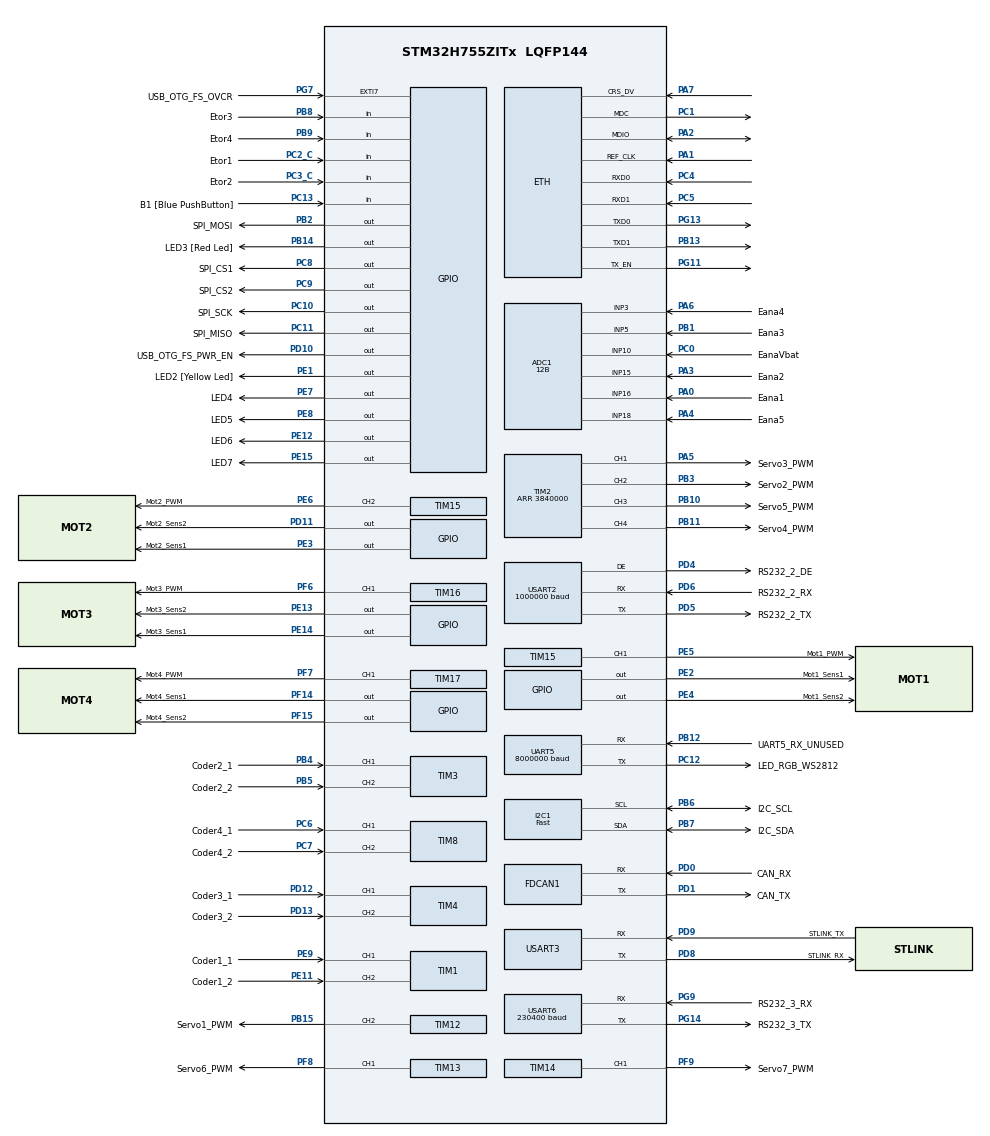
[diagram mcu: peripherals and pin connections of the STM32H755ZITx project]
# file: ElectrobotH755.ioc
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ADC1.Channel-0\#ChannelRegularConversion=ADC_CHANNEL_3
ADC1.ContinuousConvMode=DISABLE
ADC1.NbrOfConversion=1
ADC1.NbrOfConversionFlag=1
ADC1.OffsetNumber-0\#ChannelRegularConversion=ADC_OFFSET_NONE
ADC1.OffsetSignedSaturation-0\#ChannelRegularConversion=DISABLE
ADC1.Rank-0\#ChannelRegularConversion=1
ADC1.Resolution=ADC_RESOLUTION_12B
ADC1.SamplingTime-0\#ChannelRegularConversion=ADC_SAMPLETIME_1CYCLE_5
ADC1.master=1
CortexM4.IPs=FATFS_M4\:I,FREERTOS_M4\:I,IWDG2\:I,RCC,WWDG2\:I,DMA,BDMA,MDMA,NVIC2\:I,DEBUG,USB_DEVICE_M4\:I,USB_HOST_M4\:I,PDM2PCM_M4\:I,PWR,RESMGR_UTILITY,SYS_M4\:I,CORTEX_M4\:I,OPENAMP_M4\:I,VREFBUF,GPIO
CortexM7.IPs=FATFS_M7\:I,FREERTOS_M7\:I,IWDG1\:I,RCC\:I,WWDG1\:I,DMA\:I,BDMA\:I,MDMA\:I,NVIC1\:I,USART3\:I,SYS\:I,CORTEX_M7\:I,DEBUG\:I,USB_DEVICE_M7\:I,USB_HOST_M7\:I,PDM2PCM_M7\:I,PWR\:I,RESMGR_UTILITY\:I,OPENAMP_M7\:I,VREFBUF\:I,GPIO\:I,I2C1\:I,TIM15\:I,TIM1\:I,TIM4\:I,TIM16\:I,TIM17\:I,TIM8\:I,USART2\:I,USART6\:I,ADC1\:I,TIM3\:I,TIM2\:I,SPI3\:I,FDCAN1\:I,TIM12\:I,TIM13\:I,TIM14\:I,MEMORYMAP\:I,UART5\:I,ETH\:I,RNG\:I
CortexM7.Pins=PE2,PE3,PE4,PC2_C,PC3_C,PB2,PF14,PF15,PE7,PE8,PE12,PE13,PE14,PE15,PB14,PD10,PD11,PC8,PC9,PC10,PC11,PB8,PB9,PE1
Dma.Request0=USART3_TX
Dma.Request1=UART5_TX
Dma.Request2=USART6_RX
Dma.UART5_TX.1.Direction=DMA_MEMORY_TO_PERIPH
Dma.UART5_TX.1.EventEnable=DISABLE
Dma.UART5_TX.1.FIFOMode=DMA_FIFOMODE_DISABLE
Dma.UART5_TX.1.Instance=DMA1_Stream1
Dma.UART5_TX.1.MemDataAlignment=DMA_MDATAALIGN_BYTE
Dma.UART5_TX.1.MemInc=DMA_MINC_ENABLE
Dma.UART5_TX.1.Mode=DMA_NORMAL
Dma.UART5_TX.1.PeriphDataAlignment=DMA_PDATAALIGN_BYTE
Dma.UART5_TX.1.PeriphInc=DMA_PINC_DISABLE
Dma.UART5_TX.1.Polarity=HAL_DMAMUX_REQ_GEN_RISING
Dma.UART5_TX.1.Priority=DMA_PRIORITY_LOW
Dma.UART5_TX.1.RequestNumber=1
Dma.UART5_TX.1.SignalID=NONE
Dma.UART5_TX.1.SyncEnable=DISABLE
Dma.UART5_TX.1.SyncPolarity=HAL_DMAMUX_SYNC_NO_EVENT
Dma.UART5_TX.1.SyncRequestNumber=1
Dma.UART5_TX.1.SyncSignalID=NONE
Dma.USART3_TX.0.Direction=DMA_MEMORY_TO_PERIPH
Dma.USART3_TX.0.EventEnable=DISABLE
Dma.USART3_TX.0.FIFOMode=DMA_FIFOMODE_DISABLE
Dma.USART3_TX.0.Instance=DMA1_Stream0
Dma.USART3_TX.0.MemDataAlignment=DMA_MDATAALIGN_BYTE
Dma.USART3_TX.0.MemInc=DMA_MINC_ENABLE
Dma.USART3_TX.0.Mode=DMA_NORMAL
Dma.USART3_TX.0.PeriphDataAlignment=DMA_PDATAALIGN_BYTE
Dma.USART3_TX.0.PeriphInc=DMA_PINC_DISABLE
Dma.USART3_TX.0.Polarity=HAL_DMAMUX_REQ_GEN_RISING
Dma.USART3_TX.0.Priority=DMA_PRIORITY_LOW
Dma.USART3_TX.0.RequestNumber=1
Dma.USART3_TX.0.SignalID=NONE
Dma.USART3_TX.0.SyncEnable=DISABLE
Dma.USART3_TX.0.SyncPolarity=HAL_DMAMUX_SYNC_NO_EVENT
Dma.USART3_TX.0.SyncRequestNumber=1
Dma.USART3_TX.0.SyncSignalID=NONE
Dma.USART6_RX.2.Direction=DMA_PERIPH_TO_MEMORY
Dma.USART6_RX.2.EventEnable=DISABLE
Dma.USART6_RX.2.FIFOMode=DMA_FIFOMODE_DISABLE
Dma.USART6_RX.2.Instance=DMA1_Stream2
Dma.USART6_RX.2.MemDataAlignment=DMA_MDATAALIGN_BYTE
Dma.USART6_RX.2.MemInc=DMA_MINC_ENABLE
Dma.USART6_RX.2.Mode=DMA_NORMAL
Dma.USART6_RX.2.PeriphDataAlignment=DMA_PDATAALIGN_BYTE
Dma.USART6_RX.2.PeriphInc=DMA_PINC_DISABLE
Dma.USART6_RX.2.Polarity=HAL_DMAMUX_REQ_GEN_RISING
Dma.USART6_RX.2.Priority=DMA_PRIORITY_LOW
Dma.USART6_RX.2.RequestNumber=1
Dma.USART6_RX.2.SignalID=NONE
Dma.USART6_RX.2.SyncEnable=DISABLE
Dma.USART6_RX.2.SyncPolarity=HAL_DMAMUX_SYNC_NO_EVENT
Dma.USART6_RX.2.SyncRequestNumber=1
Dma.USART6_RX.2.SyncSignalID=NONE
ETH.MediaInterface=HAL_ETH_RMII_MODE
FDCAN1.CalculateBaudRateNominal=1791666
FDCAN1.CalculateTimeBitNominal=558
FDCAN1.CalculateTimeQuantumNominal=186.04651162790697
I2C1.I2C_Speed_Mode=I2C_Fast
I2C1.Timing=0x009032AE
Mcu.Family=STM32H7
Mcu.Name=STM32H755ZITx
Mcu.Package=LQFP144
NVIC1.DMA1_Stream0_IRQn=true\:0\:0\:false\:false\:true\:false\:true\:true
NVIC1.DMA1_Stream1_IRQn=true\:0\:0\:false\:false\:true\:false\:true\:true
NVIC1.DMA1_Stream2_IRQn=true\:5\:0\:true\:false\:true\:false\:true\:true
NVIC1.ETH_IRQn=true\:0\:0\:false\:false\:false\:true\:true\:true
NVIC1.PriorityGroup=NVIC_PRIORITYGROUP_4
NVIC1.UART5_IRQn=true\:0\:0\:false\:false\:true\:true\:true\:true
NVIC1.USART3_IRQn=true\:6\:0\:true\:false\:true\:true\:true\:true
NVIC1.USART6_IRQn=true\:5\:0\:true\:false\:true\:true\:true\:true
NVIC2.PriorityGroup=NVIC_PRIORITYGROUP_4
PA0.GPIO_Label=Eana1
PA0.Mode=IN16-Single-Ended
PA0.PinAttribute=CortexM7
PA0.Signal=ADC1_INP16
PA1.Mode=RMII
PA1.PinAttribute=CortexM7
PA1.Signal=ETH_REF_CLK
PA11.PinAttribute=CortexM7
PA11.Signal=USB_OTG_FS_DM
PA12.PinAttribute=CortexM7
PA12.Signal=USB_OTG_FS_DP
PA2.Mode=RMII
PA2.PinAttribute=CortexM7
PA2.Signal=ETH_MDIO
PA3.GPIO_Label=Eana2
PA3.PinAttribute=CortexM7
PA3.Signal=ADCx_INP15
PA4.GPIO_Label=Eana5
PA4.PinAttribute=CortexM7
PA4.Signal=ADCx_INP18
PA5.GPIO_Label=Servo3_PWM
PA5.PinAttribute=CortexM7
PA5.Signal=S_TIM2_CH1_ETR
PA6.GPIO_Label=Eana4
PA6.PinAttribute=CortexM7
PA6.Signal=ADCx_INP3
PA7.Mode=RMII
PA7.PinAttribute=CortexM7
PA7.Signal=ETH_CRS_DV
PA8.PinAttribute=CortexM7
PA8.Signal=USB_OTG_FS_SOF
PA9.PinAttribute=CortexM7
PA9.Signal=USB_OTG_FS_VBUS
PB0.PinAttribute=CortexM7
PB0.Signal=ETH_RXD2
PB1.GPIO_Label=Eana3
PB1.PinAttribute=CortexM7
PB1.Signal=ADCx_INP5
PB10.GPIO_Label=Servo5_PWM
PB10.PinAttribute=CortexM7
PB10.Signal=S_TIM2_CH3
PB11.GPIO_Label=Servo4_PWM
PB11.PinAttribute=CortexM7
PB11.Signal=S_TIM2_CH4
PB12.GPIO_Label=UART5_RX_UNUSED
PB12.Mode=Asynchronous
PB12.PinAttribute=CortexM7
PB12.Signal=UART5_RX
PB13.Mode=RMII
PB13.PinAttribute=CortexM7
PB13.Signal=ETH_TXD1
PB14.GPIO_Label=LED3 [Red Led]
PB14.PinAttribute=CortexM7
PB14.PinState=GPIO_PIN_SET
PB14.Signal=GPIO_Output
PB15.GPIO_Label=Servo1_PWM
PB15.PinAttribute=CortexM7
PB15.Signal=S_TIM12_CH2
PB2.GPIO_Label=SPI_MOSI
PB2.PinAttribute=CortexM7
PB2.Signal=GPIO_Output
PB3\ (JTDO/TRACESWO).GPIO_Label=Servo2_PWM
PB3\ (JTDO/TRACESWO).PinAttribute=CortexM7
PB3\ (JTDO/TRACESWO).Signal=S_TIM2_CH2
PB4\ (NJTRST).GPIO_Label=Coder2_1
PB4\ (NJTRST).PinAttribute=CortexM7
PB4\ (NJTRST).Signal=S_TIM3_CH1
PB5.GPIO_Label=Coder2_2
PB5.PinAttribute=CortexM7
PB5.Signal=S_TIM3_CH2
PB6.GPIO_Label=I2C_SCL
PB6.GPIO_Pu=GPIO_NOPULL
PB6.GPIO_Speed=GPIO_SPEED_FREQ_VERY_HIGH
PB6.Mode=I2C
PB6.PinAttribute=CortexM7
PB6.Signal=I2C1_SCL
PB7.GPIO_Label=I2C_SDA
PB7.GPIO_Pu=GPIO_NOPULL
PB7.GPIO_Speed=GPIO_SPEED_FREQ_VERY_HIGH
PB7.Mode=I2C
PB7.PinAttribute=CortexM7
PB7.Signal=I2C1_SDA
PB8.GPIO_Label=Etor3
PB8.GPIO_PuPd=GPIO_PULLUP
PB8.PinAttribute=CortexM7
PB8.Signal=GPIO_Input
PB9.GPIO_Label=Etor4
PB9.GPIO_PuPd=GPIO_PULLUP
PB9.PinAttribute=CortexM7
PB9.Signal=GPIO_Input
PC0.GPIO_Label=EanaVbat
PC0.PinAttribute=CortexM7
PC0.Signal=ADCx_INP10
PC1.Mode=RMII
PC1.PinAttribute=CortexM7
PC1.Signal=ETH_MDC
PC10.GPIO_Label=SPI_SCK
PC10.PinAttribute=CortexM7
PC10.Signal=GPIO_Output
PC11.GPIO_Label=SPI_MISO
PC11.PinAttribute=CortexM7
PC11.Signal=GPIO_Output
PC12.GPIO_Label=LED_RGB_WS2812
PC12.Mode=Asynchronous
PC12.PinAttribute=CortexM7
PC12.Signal=UART5_TX
PC13.GPIO_Label=B1 [Blue PushButton]
PC13.PinAttribute=Free
PC13.Signal=GPIO_Input
PC14-OSC32_IN\ (OSC32_IN).Mode=LSE-External-Oscillator
PC14-OSC32_IN\ (OSC32_IN).PinAttribute=CortexM7
PC14-OSC32_IN\ (OSC32_IN).Signal=RCC_OSC32_IN
PC15-OSC32_OUT\ (OSC32_OUT).Mode=LSE-External-Oscillator
PC15-OSC32_OUT\ (OSC32_OUT).PinAttribute=CortexM7
PC15-OSC32_OUT\ (OSC32_OUT).Signal=RCC_OSC32_OUT
PC2_C.GPIO_Label=Etor1
PC2_C.GPIO_PuPd=GPIO_PULLUP
PC2_C.PinAttribute=CortexM7
PC2_C.Signal=GPIO_Input
PC3_C.GPIO_Label=Etor2
PC3_C.GPIO_PuPd=GPIO_PULLUP
PC3_C.PinAttribute=CortexM7
PC3_C.Signal=GPIO_Input
PC4.Mode=RMII
PC4.PinAttribute=CortexM7
PC4.Signal=ETH_RXD0
PC5.Mode=RMII
PC5.PinAttribute=CortexM7
PC5.Signal=ETH_RXD1
PC6.GPIO_Label=Coder4_1
PC6.PinAttribute=CortexM7
PC6.Signal=S_TIM8_CH1
PC7.GPIO_Label=Coder4_2
PC7.PinAttribute=CortexM7
PC7.Signal=S_TIM8_CH2
PC8.GPIO_Label=SPI_CS1
PC8.PinAttribute=CortexM7
PC8.Signal=GPIO_Output
PC9.GPIO_Label=SPI_CS2
PC9.PinAttribute=CortexM7
PC9.Signal=GPIO_Output
PD0.GPIO_Label=CAN_RX
PD0.Mode=FDCAN_Activate
PD0.PinAttribute=CortexM7
PD0.Signal=FDCAN1_RX
PD1.GPIO_Label=CAN_TX
PD1.GPIO_PuPd=GPIO_PULLUP
PD1.Mode=FDCAN_Activate
PD1.PinAttribute=CortexM7
PD1.Signal=FDCAN1_TX
PD10.GPIO_Label=USB_OTG_FS_PWR_EN
PD10.PinAttribute=CortexM7
PD10.Signal=GPIO_Output
PD11.GPIO_Label=Mot2_Sens2
PD11.PinAttribute=CortexM7
PD11.Signal=GPIO_Output
PD12.GPIO_Label=Coder3_1
PD12.PinAttribute=CortexM7
PD12.Signal=S_TIM4_CH1
PD13.GPIO_Label=Coder3_2
PD13.PinAttribute=CortexM7
PD13.Signal=S_TIM4_CH2
PD4.GPIO_Label=RS232_2_DE
PD4.Mode=Hardware Flow Control (RS485)
PD4.PinAttribute=CortexM7
PD4.Signal=USART2_DE
PD5.GPIO_Label=RS232_2_TX
PD5.Mode=Asynchronous
PD5.PinAttribute=CortexM7
PD5.Signal=USART2_TX
PD6.GPIO_Label=RS232_2_RX
PD6.Mode=Asynchronous
PD6.PinAttribute=CortexM7
PD6.Signal=USART2_RX
PD8.GPIO_Label=STLINK_RX
PD8.Mode=Asynchronous
PD8.PinAttribute=CortexM7
PD8.Signal=USART3_TX
PD9.GPIO_Label=STLINK_TX
PD9.Mode=Asynchronous
PD9.PinAttribute=CortexM7
PD9.Signal=USART3_RX
PE1.GPIO_Label=LED2 [Yellow Led]
PE1.PinAttribute=CortexM7
PE1.Signal=GPIO_Output
PE11.GPIO_Label=Coder1_2
PE11.PinAttribute=CortexM7
PE11.Signal=S_TIM1_CH2
PE12.GPIO_Label=LED6
PE12.PinAttribute=CortexM7
PE12.Signal=GPIO_Output
PE13.GPIO_Label=Mot3_Sens2
PE13.PinAttribute=CortexM7
PE13.Signal=GPIO_Output
PE14.GPIO_Label=Mot3_Sens1
PE14.PinAttribute=CortexM7
PE14.Signal=GPIO_Output
PE15.GPIO_Label=LED7
PE15.PinAttribute=CortexM7
PE15.Signal=GPIO_Output
PE2.GPIO_Label=Mot1_Sens1
PE2.PinAttribute=CortexM7
PE2.Signal=GPIO_Output
PE3.GPIO_Label=Mot2_Sens1
PE3.PinAttribute=CortexM7
PE3.Signal=GPIO_Output
PE4.GPIO_Label=Mot1_Sens2
PE4.PinAttribute=CortexM7
PE4.Signal=GPIO_Output
PE5.GPIO_Label=Mot1_PWM
PE5.PinAttribute=CortexM7
PE5.Signal=S_TIM15_CH1
PE6.GPIO_Label=Mot2_PWM
PE6.PinAttribute=CortexM7
PE6.Signal=S_TIM15_CH2
PE7.GPIO_Label=LED4
PE7.PinAttribute=CortexM7
PE7.Signal=GPIO_Output
PE8.GPIO_Label=LED5
PE8.PinAttribute=CortexM7
PE8.Signal=GPIO_Output
PE9.GPIO_Label=Coder1_1
PE9.PinAttribute=CortexM7
PE9.Signal=S_TIM1_CH1
PF14.GPIO_Label=Mot4_Sens1
PF14.PinAttribute=CortexM7
PF14.Signal=GPIO_Output
PF15.GPIO_Label=Mot4_Sens2
PF15.PinAttribute=CortexM7
PF15.Signal=GPIO_Output
PF6.GPIO_Label=Mot3_PWM
PF6.PinAttribute=CortexM7
PF6.Signal=S_TIM16_CH1
PF7.GPIO_Label=Mot4_PWM
PF7.PinAttribute=CortexM7
PF7.Signal=S_TIM17_CH1
PF8.GPIO_Label=Servo6_PWM
PF8.PinAttribute=CortexM7
PF8.Signal=S_TIM13_CH1
PF9.GPIO_Label=Servo7_PWM
PF9.PinAttribute=CortexM7
PF9.Signal=S_TIM14_CH1
PG11.Mode=RMII
PG11.PinAttribute=CortexM7
PG11.Signal=ETH_TX_EN
PG13.Mode=RMII
PG13.PinAttribute=CortexM7
PG13.Signal=ETH_TXD0
PG14.GPIO_Label=RS232_3_TX
PG14.Mode=Asynchronous
PG14.PinAttribute=CortexM7
PG14.Signal=USART6_TX
PG7.GPIO_Label=USB_OTG_FS_OVCR
PG7.PinAttribute=Free
PG7.Signal=GPXTI7
PG9.GPIO_Label=RS232_3_RX
PG9.Mode=Asynchronous
PG9.PinAttribute=CortexM7
PG9.Signal=USART6_RX
PH0-OSC_IN\ (PH0).Mode=HSE-External-Clock-Source
PH0-OSC_IN\ (PH0).PinAttribute=CortexM7
PH0-OSC_IN\ (PH0).Signal=RCC_OSC_IN
PH1-OSC_OUT\ (PH1).PinAttribute=CortexM7
PH1-OSC_OUT\ (PH1).Signal=RCC_OSC_OUT
ProjectManager.HeapSize=M4-0x200,M7-0x200
ProjectManager.StackSize=M4-0x400,M7-0x400
ProjectManager.TargetToolchain=STM32CubeIDE
RCC.ADCCLockSelection=RCC_ADCCLKSOURCE_PLL3
RCC.ADCFreq_Value=17200000
RCC.APB1Freq_Value=96000000
RCC.APB2Freq_Value=96000000
RCC.APB3Freq_Value=96000000
RCC.APB4Freq_Value=96000000
RCC.CortexFreq_Value=384000000
RCC.D1PPRE=RCC_APB3_DIV2
RCC.D2PPRE1=RCC_APB1_DIV2
RCC.D2PPRE2=RCC_APB2_DIV2
RCC.D3PPRE=RCC_APB4_DIV2
RCC.DIVM1=1
RCC.DIVM2=4
RCC.DIVM3=5
RCC.DIVN1=96
RCC.DIVQ1=4
RCC.DIVQ2=3
RCC.DIVR3=12
RCC.FDCANCLockSelection=RCC_FDCANCLKSOURCE_PLL2
RCC.HCLKFreq_Value=192000000
RCC.HPRE=RCC_HCLK_DIV2
RCC.HSE_VALUE=8000000
RCC.PLL2_VCI_Range-AdvancedSettings=RCC_PLL2VCIRANGE_1
RCC.PLL3_VCI_Range-AdvancedSettings=RCC_PLL3VCIRANGE_1
RCC.PLLSourceVirtual=RCC_PLLSOURCE_HSE
RCC.SYSCLKFreq_VALUE=384000000
RCC.SYSCLKSource=RCC_SYSCLKSOURCE_PLLCLK
RCC.SupplySource=PWR_DIRECT_SMPS_SUPPLY
RCC.USBFreq_Value=192000000
SH.ADCx_INP10.0=ADC1_INP10,IN10-Single-Ended
SH.ADCx_INP15.0=ADC1_INP15,IN15-Single-Ended
SH.ADCx_INP18.0=ADC1_INP18,IN18-Single-Ended
SH.ADCx_INP3.0=ADC1_INP3,IN3-Single-Ended
SH.ADCx_INP5.0=ADC1_INP5,IN5-Single-Ended
SH.S_TIM12_CH2.0=TIM12_CH2,PWM Generation2 CH2
SH.S_TIM13_CH1.0=TIM13_CH1,PWM Generation1 CH1
SH.S_TIM14_CH1.0=TIM14_CH1,PWM Generation1 CH1
SH.S_TIM15_CH1.0=TIM15_CH1,PWM Generation1 CH1
SH.S_TIM15_CH2.0=TIM15_CH2,PWM Generation2 CH2
SH.S_TIM16_CH1.0=TIM16_CH1,PWM Generation1 CH1
SH.S_TIM17_CH1.0=TIM17_CH1,PWM Generation1 CH1
SH.S_TIM1_CH1.0=TIM1_CH1,Encoder_Interface
SH.S_TIM1_CH2.0=TIM1_CH2,Encoder_Interface
SH.S_TIM2_CH1_ETR.0=TIM2_CH1,PWM Generation1 CH1
SH.S_TIM2_CH2.0=TIM2_CH2,PWM Generation2 CH2
SH.S_TIM2_CH3.0=TIM2_CH3,PWM Generation3 CH3
SH.S_TIM2_CH4.0=TIM2_CH4,PWM Generation4 CH4
SH.S_TIM3_CH1.0=TIM3_CH1,Encoder_Interface
SH.S_TIM3_CH2.0=TIM3_CH2,Encoder_Interface
SH.S_TIM4_CH1.0=TIM4_CH1,Encoder_Interface
SH.S_TIM4_CH2.0=TIM4_CH2,Encoder_Interface
SH.S_TIM8_CH1.0=TIM8_CH1,Encoder_Interface
SH.S_TIM8_CH2.0=TIM8_CH2,Encoder_Interface
TIM1.EncoderMode=TIM_ENCODERMODE_TI12
TIM12.Channel-PWM\ Generation2\ CH2=TIM_CHANNEL_2
TIM12.Period=64000
TIM12.Prescaler=59
TIM13.Channel=TIM_CHANNEL_1
TIM13.Period=64000
TIM13.Prescaler=59
TIM14.Channel=TIM_CHANNEL_1
TIM14.Period=64000
TIM14.Prescaler=59
TIM15.Channel-PWM\ Generation1\ CH1=TIM_CHANNEL_1
TIM15.Channel-PWM\ Generation2\ CH2=TIM_CHANNEL_2
TIM15.Period=9600
TIM15.Prescaler=0
TIM16.Channel=TIM_CHANNEL_1
TIM16.Period=9600
TIM16.Pulse=10000
TIM17.Channel=TIM_CHANNEL_1
TIM17.Period=9600
TIM17.Pulse=45000
TIM2.Channel-PWM\ Generation1\ CH1=TIM_CHANNEL_1
TIM2.Channel-PWM\ Generation2\ CH2=TIM_CHANNEL_2
TIM2.Channel-PWM\ Generation3\ CH3=TIM_CHANNEL_3
TIM2.Channel-PWM\ Generation4\ CH4=TIM_CHANNEL_4
TIM2.Period=3840000
TIM3.EncoderMode=TIM_ENCODERMODE_TI12
TIM4.EncoderMode=TIM_ENCODERMODE_TI12
TIM8.EncoderMode=TIM_ENCODERMODE_TI12
UART5.BaudRate=8000000
UART5.Mode=MODE_TX
UART5.OverSampling=UART_OVERSAMPLING_8
UART5.TxPinLevelInvertParam=UART_ADVFEATURE_TXINV_ENABLE
USART2.BaudRate=1000000
USART2.UART_DEAssertionTime=25
USART2.UART_DEDeassertionTime=25
USART2.VirtualMode-Asynchronous=VM_ASYNC
USART2.VirtualMode-Hardware\ Flow\ Control\ (RS485)=VM_ASYNC
USART3.VirtualMode-Asynchronous=VM_ASYNC
USART6.BaudRate=230400
USART6.VirtualMode-Asynchronous=VM_ASYNC
VP_MEMORYMAP_VS_MEMORYMAP.Mode=CurAppReg
VP_RNG_VS_RNG.Mode=RNG_Activate
VP_SYS_M4_VS_Systick.Mode=SysTick
VP_TIM13_VS_ClockSourceINT.Mode=Enable_Timer
VP_TIM14_VS_ClockSourceINT.Mode=Enable_Timer
VP_TIM16_VS_ClockSourceINT.Mode=Enable_Timer
VP_TIM17_VS_ClockSourceINT.Mode=Enable_Timer
board=NUCLEO-H755ZI-Q

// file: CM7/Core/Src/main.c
/* USER CODE BEGIN Header */
/**
  ******************************************************************************
  * @file           : main.c
  * @brief          : Main program body
  ******************************************************************************
  * @attention
  *
  * Copyright (c) 2025 STMicroelectronics.
  * All rights reserved.
  *
  * This software is licensed under terms that can be found in the LICENSE file
  * in the root directory of this software component.
  * If no LICENSE file comes with this software, it is provided AS-IS.
  *
  ******************************************************************************
  */
/* USER CODE END Header */
#include "main.h"
#include "string.h"

/* USER CODE BEGIN PD */

#ifndef HSEM_ID_0
#define HSEM_ID_0 (0U) /* HW semaphore 0*/
#endif

/* USER CODE END PD */

#if defined ( __ICCARM__ ) /*!< IAR Compiler */
#pragma location=0x30000000
ETH_DMADescTypeDef  DMARxDscrTab[ETH_RX_DESC_CNT]; /* Ethernet Rx DMA Descriptors */
#pragma location=0x30000080
ETH_DMADescTypeDef  DMATxDscrTab[ETH_TX_DESC_CNT]; /* Ethernet Tx DMA Descriptors */

#elif defined ( __CC_ARM )  /* MDK ARM Compiler */

__attribute__((at(0x30000000))) ETH_DMADescTypeDef  DMARxDscrTab[ETH_RX_DESC_CNT]; /* Ethernet Rx DMA Descriptors */
__attribute__((at(0x30000080))) ETH_DMADescTypeDef  DMATxDscrTab[ETH_TX_DESC_CNT]; /* Ethernet Tx DMA Descriptors */

#elif defined ( __GNUC__ ) /* GNU Compiler */

ETH_DMADescTypeDef DMARxDscrTab[ETH_RX_DESC_CNT] __attribute__((section(".RxDescripSection"))); /* Ethernet Rx DMA Descriptors */
ETH_DMADescTypeDef DMATxDscrTab[ETH_TX_DESC_CNT] __attribute__((section(".TxDescripSection")));   /* Ethernet Tx DMA Descriptors */
#endif

ETH_TxPacketConfig TxConfig;

ADC_HandleTypeDef hadc1;

ETH_HandleTypeDef heth;

FDCAN_HandleTypeDef hfdcan1;

I2C_HandleTypeDef hi2c1;

RNG_HandleTypeDef hrng;

TIM_HandleTypeDef htim1;
TIM_HandleTypeDef htim2;
TIM_HandleTypeDef htim3;
TIM_HandleTypeDef htim4;
TIM_HandleTypeDef htim8;
TIM_HandleTypeDef htim12;
TIM_HandleTypeDef htim13;
TIM_HandleTypeDef htim14;
TIM_HandleTypeDef htim15;
TIM_HandleTypeDef htim16;
TIM_HandleTypeDef htim17;

UART_HandleTypeDef huart5;
UART_HandleTypeDef huart2;
UART_HandleTypeDef huart3;
UART_HandleTypeDef huart6;
DMA_HandleTypeDef hdma_uart5_tx;
DMA_HandleTypeDef hdma_usart3_tx;
DMA_HandleTypeDef hdma_usart6_rx;

void SystemClock_Config(void);
static void MX_GPIO_Init(void);
static void MX_DMA_Init(void);
static void MX_I2C1_Init(void);
static void MX_TIM15_Init(void);
static void MX_TIM1_Init(void);
static void MX_TIM2_Init(void);
static void MX_TIM4_Init(void);
static void MX_TIM8_Init(void);
static void MX_TIM16_Init(void);
static void MX_TIM17_Init(void);
static void MX_USART2_UART_Init(void);
static void MX_USART6_UART_Init(void);
static void MX_USART3_UART_Init(void);
static void MX_ADC1_Init(void);
static void MX_TIM3_Init(void);
static void MX_FDCAN1_Init(void);
static void MX_TIM12_Init(void);
static void MX_TIM13_Init(void);
static void MX_TIM14_Init(void);
static void MX_UART5_Init(void);
static void MX_ETH_Init(void);
static void MX_RNG_Init(void);

int main(void)
{

/* USER CODE BEGIN Boot_Mode_Sequence_0 */
  int32_t timeout;
/* USER CODE END Boot_Mode_Sequence_0 */

/* USER CODE BEGIN Boot_Mode_Sequence_1 */
  /* Wait until CPU2 boots and enters in stop mode or timeout*/
  timeout = 0xFFFF;
  while((__HAL_RCC_GET_FLAG(RCC_FLAG_D2CKRDY) != RESET) && (timeout-- > 0));
  if ( timeout < 0 )
  {
  Error_Handler();
  }
/* USER CODE END Boot_Mode_Sequence_1 */
  /* MCU Configuration--------------------------------------------------------*/

  /* Reset of all peripherals, Initializes the Flash interface and the Systick. */
  HAL_Init();

  /* Configure the system clock */
  SystemClock_Config();
/* USER CODE BEGIN Boot_Mode_Sequence_2 */
/* When system initialization is finished, Cortex-M7 will release Cortex-M4 by means of
HSEM notification */
/*HW semaphore Clock enable*/
__HAL_RCC_HSEM_CLK_ENABLE();
/*Take HSEM */
HAL_HSEM_FastTake(HSEM_ID_0);
/*Release HSEM in order to notify the CPU2(CM4)*/
HAL_HSEM_Release(HSEM_ID_0,0);
/* wait until CPU2 wakes up from stop mode */
timeout = 0xFFFF;
while((__HAL_RCC_GET_FLAG(RCC_FLAG_D2CKRDY) == RESET) && (timeout-- > 0));
if ( timeout < 0 )
{
Error_Handler();
}
/* USER CODE END Boot_Mode_Sequence_2 */

  /* Initialize all configured peripherals */
  MX_GPIO_Init();
  MX_DMA_Init();
  MX_I2C1_Init();
  MX_TIM15_Init();
  MX_TIM1_Init();
  MX_TIM2_Init();
  MX_TIM4_Init();
  MX_TIM8_Init();
  MX_TIM16_Init();
  MX_TIM17_Init();
  MX_USART2_UART_Init();
  MX_USART6_UART_Init();
  MX_USART3_UART_Init();
  MX_ADC1_Init();
  MX_TIM3_Init();
  MX_FDCAN1_Init();
  MX_TIM12_Init();
  MX_TIM13_Init();
  MX_TIM14_Init();
  MX_UART5_Init();
  MX_ETH_Init();
  MX_RNG_Init();
  /* USER CODE BEGIN 2 */
  main_app();

  /* USER CODE END 2 */

  /* Infinite loop */
  while (1)
  {

  }
}

void SystemClock_Config(void)
{
  RCC_OscInitTypeDef RCC_OscInitStruct = {0};
  RCC_ClkInitTypeDef RCC_ClkInitStruct = {0};

  /** Supply configuration update enable
  */
  HAL_PWREx_ConfigSupply(PWR_DIRECT_SMPS_SUPPLY);

  /** Configure the main internal regulator output voltage
  */
  __HAL_PWR_VOLTAGESCALING_CONFIG(PWR_REGULATOR_VOLTAGE_SCALE1);

  while(!__HAL_PWR_GET_FLAG(PWR_FLAG_VOSRDY)) {}

  /** Initializes the RCC Oscillators according to the specified parameters
  * in the RCC_OscInitTypeDef structure.
  */
  RCC_OscInitStruct.OscillatorType = RCC_OSCILLATORTYPE_HSI48|RCC_OSCILLATORTYPE_HSE;
  RCC_OscInitStruct.HSEState = RCC_HSE_BYPASS;
  RCC_OscInitStruct.HSI48State = RCC_HSI48_ON;
  RCC_OscInitStruct.PLL.PLLState = RCC_PLL_ON;
  RCC_OscInitStruct.PLL.PLLSource = RCC_PLLSOURCE_HSE;
  RCC_OscInitStruct.PLL.PLLM = 1;
  RCC_OscInitStruct.PLL.PLLN = 96;
  RCC_OscInitStruct.PLL.PLLP = 2;
  RCC_OscInitStruct.PLL.PLLQ = 4;
  RCC_OscInitStruct.PLL.PLLR = 2;
  RCC_OscInitStruct.PLL.PLLRGE = RCC_PLL1VCIRANGE_3;
  RCC_OscInitStruct.PLL.PLLVCOSEL = RCC_PLL1VCOWIDE;
  RCC_OscInitStruct.PLL.PLLFRACN = 0;
  if (HAL_RCC_OscConfig(&RCC_OscInitStruct) != HAL_OK)
  {
    Error_Handler();
  }

  /** Initializes the CPU, AHB and APB buses clocks
  */
  RCC_ClkInitStruct.ClockType = RCC_CLOCKTYPE_HCLK|RCC_CLOCKTYPE_SYSCLK
                              |RCC_CLOCKTYPE_PCLK1|RCC_CLOCKTYPE_PCLK2
                              |RCC_CLOCKTYPE_D3PCLK1|RCC_CLOCKTYPE_D1PCLK1;
  RCC_ClkInitStruct.SYSCLKSource = RCC_SYSCLKSOURCE_PLLCLK;
  RCC_ClkInitStruct.SYSCLKDivider = RCC_SYSCLK_DIV1;
  RCC_ClkInitStruct.AHBCLKDivider = RCC_HCLK_DIV2;
  RCC_ClkInitStruct.APB3CLKDivider = RCC_APB3_DIV2;
  RCC_ClkInitStruct.APB1CLKDivider = RCC_APB1_DIV2;
  RCC_ClkInitStruct.APB2CLKDivider = RCC_APB2_DIV2;
  RCC_ClkInitStruct.APB4CLKDivider = RCC_APB4_DIV2;

  if (HAL_RCC_ClockConfig(&RCC_ClkInitStruct, FLASH_LATENCY_2) != HAL_OK)
  {
    Error_Handler();
  }
}

static void MX_ADC1_Init(void)
{

  ADC_MultiModeTypeDef multimode = {0};
  ADC_ChannelConfTypeDef sConfig = {0};

  /** Common config
  */
  hadc1.Instance = ADC1;
  hadc1.Init.ClockPrescaler = ADC_CLOCK_ASYNC_DIV1;
  hadc1.Init.Resolution = ADC_RESOLUTION_12B;
  hadc1.Init.ScanConvMode = ADC_SCAN_DISABLE;
  hadc1.Init.EOCSelection = ADC_EOC_SINGLE_CONV;
  hadc1.Init.LowPowerAutoWait = DISABLE;
  hadc1.Init.ContinuousConvMode = DISABLE;
  hadc1.Init.NbrOfConversion = 1;
  hadc1.Init.DiscontinuousConvMode = DISABLE;
  hadc1.Init.ExternalTrigConv = ADC_SOFTWARE_START;
  hadc1.Init.ExternalTrigConvEdge = ADC_EXTERNALTRIGCONVEDGE_NONE;
  hadc1.Init.ConversionDataManagement = ADC_CONVERSIONDATA_DR;
  hadc1.Init.Overrun = ADC_OVR_DATA_PRESERVED;
  hadc1.Init.LeftBitShift = ADC_LEFTBITSHIFT_NONE;
  hadc1.Init.OversamplingMode = DISABLE;
  hadc1.Init.Oversampling.Ratio = 1;
  if (HAL_ADC_Init(&hadc1) != HAL_OK)
  {
    Error_Handler();
  }

  /** Configure the ADC multi-mode
  */
  multimode.Mode = ADC_MODE_INDEPENDENT;
  if (HAL_ADCEx_MultiModeConfigChannel(&hadc1, &multimode) != HAL_OK)
  {
    Error_Handler();
  }

  /** Configure Regular Channel
  */
  sConfig.Channel = ADC_CHANNEL_3;
  sConfig.Rank = ADC_REGULAR_RANK_1;
  sConfig.SamplingTime = ADC_SAMPLETIME_1CYCLE_5;
  sConfig.SingleDiff = ADC_SINGLE_ENDED;
  sConfig.OffsetNumber = ADC_OFFSET_NONE;
  sConfig.Offset = 0;
  sConfig.OffsetSignedSaturation = DISABLE;
  if (HAL_ADC_ConfigChannel(&hadc1, &sConfig) != HAL_OK)
  {
    Error_Handler();
  }

}

static void MX_ETH_Init(void)
{

   static uint8_t MACAddr[6];

  heth.Instance = ETH;
  MACAddr[0] = 0x00;
  MACAddr[1] = 0x80;
  MACAddr[2] = 0xE1;
  MACAddr[3] = 0x00;
  MACAddr[4] = 0x00;
  MACAddr[5] = 0x00;
  heth.Init.MACAddr = &MACAddr[0];
  heth.Init.MediaInterface = HAL_ETH_RMII_MODE;
  heth.Init.TxDesc = DMATxDscrTab;
  heth.Init.RxDesc = DMARxDscrTab;
  heth.Init.RxBuffLen = 1524;

  if (HAL_ETH_Init(&heth) != HAL_OK)
  {
    Error_Handler();
  }

  memset(&TxConfig, 0 , sizeof(ETH_TxPacketConfig));
  TxConfig.Attributes = ETH_TX_PACKETS_FEATURES_CSUM | ETH_TX_PACKETS_FEATURES_CRCPAD;
  TxConfig.ChecksumCtrl = ETH_CHECKSUM_IPHDR_PAYLOAD_INSERT_PHDR_CALC;
  TxConfig.CRCPadCtrl = ETH_CRC_PAD_INSERT;

}

static void MX_FDCAN1_Init(void)
{

  hfdcan1.Instance = FDCAN1;
  hfdcan1.Init.FrameFormat = FDCAN_FRAME_CLASSIC;
  hfdcan1.Init.Mode = FDCAN_MODE_NORMAL;
  hfdcan1.Init.AutoRetransmission = DISABLE;
  hfdcan1.Init.TransmitPause = DISABLE;
  hfdcan1.Init.ProtocolException = DISABLE;
  hfdcan1.Init.NominalPrescaler = 16;
  hfdcan1.Init.NominalSyncJumpWidth = 1;
  hfdcan1.Init.NominalTimeSeg1 = 1;
  hfdcan1.Init.NominalTimeSeg2 = 1;
  hfdcan1.Init.DataPrescaler = 1;
  hfdcan1.Init.DataSyncJumpWidth = 1;
  hfdcan1.Init.DataTimeSeg1 = 1;
  hfdcan1.Init.DataTimeSeg2 = 1;
  hfdcan1.Init.MessageRAMOffset = 0;
  hfdcan1.Init.StdFiltersNbr = 0;
  hfdcan1.Init.ExtFiltersNbr = 0;
  hfdcan1.Init.RxFifo0ElmtsNbr = 0;
  hfdcan1.Init.RxFifo0ElmtSize = FDCAN_DATA_BYTES_8;
  hfdcan1.Init.RxFifo1ElmtsNbr = 0;
  hfdcan1.Init.RxFifo1ElmtSize = FDCAN_DATA_BYTES_8;
  hfdcan1.Init.RxBuffersNbr = 0;
  hfdcan1.Init.RxBufferSize = FDCAN_DATA_BYTES_8;
  hfdcan1.Init.TxEventsNbr = 0;
  hfdcan1.Init.TxBuffersNbr = 0;
  hfdcan1.Init.TxFifoQueueElmtsNbr = 0;
  hfdcan1.Init.TxFifoQueueMode = FDCAN_TX_FIFO_OPERATION;
  hfdcan1.Init.TxElmtSize = FDCAN_DATA_BYTES_8;
  if (HAL_FDCAN_Init(&hfdcan1) != HAL_OK)
  {
    Error_Handler();
  }

}

static void MX_I2C1_Init(void)
{

  hi2c1.Instance = I2C1;
  hi2c1.Init.Timing = 0x009032AE;
  hi2c1.Init.OwnAddress1 = 0;
  hi2c1.Init.AddressingMode = I2C_ADDRESSINGMODE_7BIT;
  hi2c1.Init.DualAddressMode = I2C_DUALADDRESS_DISABLE;
  hi2c1.Init.OwnAddress2 = 0;
  hi2c1.Init.OwnAddress2Masks = I2C_OA2_NOMASK;
  hi2c1.Init.GeneralCallMode = I2C_GENERALCALL_DISABLE;
  hi2c1.Init.NoStretchMode = I2C_NOSTRETCH_DISABLE;
  if (HAL_I2C_Init(&hi2c1) != HAL_OK)
  {
    Error_Handler();
  }

  /** Configure Analogue filter
  */
  if (HAL_I2CEx_ConfigAnalogFilter(&hi2c1, I2C_ANALOGFILTER_ENABLE) != HAL_OK)
  {
    Error_Handler();
  }

  /** Configure Digital filter
  */
  if (HAL_I2CEx_ConfigDigitalFilter(&hi2c1, 0) != HAL_OK)
  {
    Error_Handler();
  }

}

static void MX_RNG_Init(void)
{

  hrng.Instance = RNG;
  hrng.Init.ClockErrorDetection = RNG_CED_ENABLE;
  if (HAL_RNG_Init(&hrng) != HAL_OK)
  {
    Error_Handler();
  }

}

static void MX_TIM1_Init(void)
{

  TIM_Encoder_InitTypeDef sConfig = {0};
  TIM_MasterConfigTypeDef sMasterConfig = {0};

  htim1.Instance = TIM1;
  htim1.Init.Prescaler = 0;
  htim1.Init.CounterMode = TIM_COUNTERMODE_UP;
  htim1.Init.Period = 65535;
  htim1.Init.ClockDivision = TIM_CLOCKDIVISION_DIV1;
  htim1.Init.RepetitionCounter = 0;
  htim1.Init.AutoReloadPreload = TIM_AUTORELOAD_PRELOAD_DISABLE;
  sConfig.EncoderMode = TIM_ENCODERMODE_TI12;
  sConfig.IC1Polarity = TIM_ICPOLARITY_RISING;
  sConfig.IC1Selection = TIM_ICSELECTION_DIRECTTI;
  sConfig.IC1Prescaler = TIM_ICPSC_DIV1;
  sConfig.IC1Filter = 0;
  sConfig.IC2Polarity = TIM_ICPOLARITY_RISING;
  sConfig.IC2Selection = TIM_ICSELECTION_DIRECTTI;
  sConfig.IC2Prescaler = TIM_ICPSC_DIV1;
  sConfig.IC2Filter = 0;
  if (HAL_TIM_Encoder_Init(&htim1, &sConfig) != HAL_OK)
  {
    Error_Handler();
  }
  sMasterConfig.MasterOutputTrigger = TIM_TRGO_RESET;
  sMasterConfig.MasterOutputTrigger2 = TIM_TRGO2_RESET;
  sMasterConfig.MasterSlaveMode = TIM_MASTERSLAVEMODE_DISABLE;
  if (HAL_TIMEx_MasterConfigSynchronization(&htim1, &sMasterConfig) != HAL_OK)
  {
    Error_Handler();
  }

}

static void MX_TIM2_Init(void)
{

  TIM_MasterConfigTypeDef sMasterConfig = {0};
  TIM_OC_InitTypeDef sConfigOC = {0};

  htim2.Instance = TIM2;
  htim2.Init.Prescaler = 0;
  htim2.Init.CounterMode = TIM_COUNTERMODE_UP;
  htim2.Init.Period = 3840000;
  htim2.Init.ClockDivision = TIM_CLOCKDIVISION_DIV1;
  htim2.Init.AutoReloadPreload = TIM_AUTORELOAD_PRELOAD_DISABLE;
  if (HAL_TIM_PWM_Init(&htim2) != HAL_OK)
  {
    Error_Handler();
  }
  sMasterConfig.MasterOutputTrigger = TIM_TRGO_RESET;
  sMasterConfig.MasterSlaveMode = TIM_MASTERSLAVEMODE_DISABLE;
  if (HAL_TIMEx_MasterConfigSynchronization(&htim2, &sMasterConfig) != HAL_OK)
  {
    Error_Handler();
  }
  sConfigOC.OCMode = TIM_OCMODE_PWM1;
  sConfigOC.Pulse = 0;
  sConfigOC.OCPolarity = TIM_OCPOLARITY_HIGH;
  sConfigOC.OCFastMode = TIM_OCFAST_DISABLE;
  if (HAL_TIM_PWM_ConfigChannel(&htim2, &sConfigOC, TIM_CHANNEL_1) != HAL_OK)
  {
    Error_Handler();
  }
  if (HAL_TIM_PWM_ConfigChannel(&htim2, &sConfigOC, TIM_CHANNEL_2) != HAL_OK)
  {
    Error_Handler();
  }
  if (HAL_TIM_PWM_ConfigChannel(&htim2, &sConfigOC, TIM_CHANNEL_3) != HAL_OK)
  {
    Error_Handler();
  }
  if (HAL_TIM_PWM_ConfigChannel(&htim2, &sConfigOC, TIM_CHANNEL_4) != HAL_OK)
  {
    Error_Handler();
  }
  HAL_TIM_MspPostInit(&htim2);

}

static void MX_TIM3_Init(void)
{

  TIM_Encoder_InitTypeDef sConfig = {0};
  TIM_MasterConfigTypeDef sMasterConfig = {0};

  htim3.Instance = TIM3;
  htim3.Init.Prescaler = 0;
  htim3.Init.CounterMode = TIM_COUNTERMODE_UP;
  htim3.Init.Period = 65535;
  htim3.Init.ClockDivision = TIM_CLOCKDIVISION_DIV1;
  htim3.Init.AutoReloadPreload = TIM_AUTORELOAD_PRELOAD_DISABLE;
  sConfig.EncoderMode = TIM_ENCODERMODE_TI12;
  sConfig.IC1Polarity = TIM_ICPOLARITY_RISING;
  sConfig.IC1Selection = TIM_ICSELECTION_DIRECTTI;
  sConfig.IC1Prescaler = TIM_ICPSC_DIV1;
  sConfig.IC1Filter = 0;
  sConfig.IC2Polarity = TIM_ICPOLARITY_RISING;
  sConfig.IC2Selection = TIM_ICSELECTION_DIRECTTI;
  sConfig.IC2Prescaler = TIM_ICPSC_DIV1;
  sConfig.IC2Filter = 0;
  if (HAL_TIM_Encoder_Init(&htim3, &sConfig) != HAL_OK)
  {
    Error_Handler();
  }
  sMasterConfig.MasterOutputTrigger = TIM_TRGO_RESET;
  sMasterConfig.MasterSlaveMode = TIM_MASTERSLAVEMODE_DISABLE;
  if (HAL_TIMEx_MasterConfigSynchronization(&htim3, &sMasterConfig) != HAL_OK)
  {
    Error_Handler();
  }

}

static void MX_TIM4_Init(void)
{

  TIM_Encoder_InitTypeDef sConfig = {0};
  TIM_MasterConfigTypeDef sMasterConfig = {0};

  htim4.Instance = TIM4;
  htim4.Init.Prescaler = 0;
  htim4.Init.CounterMode = TIM_COUNTERMODE_UP;
  htim4.Init.Period = 65535;
  htim4.Init.ClockDivision = TIM_CLOCKDIVISION_DIV1;
  htim4.Init.AutoReloadPreload = TIM_AUTORELOAD_PRELOAD_DISABLE;
  sConfig.EncoderMode = TIM_ENCODERMODE_TI12;
  sConfig.IC1Polarity = TIM_ICPOLARITY_RISING;
  sConfig.IC1Selection = TIM_ICSELECTION_DIRECTTI;
  sConfig.IC1Prescaler = TIM_ICPSC_DIV1;
  sConfig.IC1Filter = 0;
  sConfig.IC2Polarity = TIM_ICPOLARITY_RISING;
  sConfig.IC2Selection = TIM_ICSELECTION_DIRECTTI;
  sConfig.IC2Prescaler = TIM_ICPSC_DIV1;
  sConfig.IC2Filter = 0;
  if (HAL_TIM_Encoder_Init(&htim4, &sConfig) != HAL_OK)
  {
    Error_Handler();
  }
  sMasterConfig.MasterOutputTrigger = TIM_TRGO_RESET;
  sMasterConfig.MasterSlaveMode = TIM_MASTERSLAVEMODE_DISABLE;
  if (HAL_TIMEx_MasterConfigSynchronization(&htim4, &sMasterConfig) != HAL_OK)
  {
    Error_Handler();
  }

}

static void MX_TIM8_Init(void)
{

  TIM_Encoder_InitTypeDef sConfig = {0};
  TIM_MasterConfigTypeDef sMasterConfig = {0};

  htim8.Instance = TIM8;
  htim8.Init.Prescaler = 0;
  htim8.Init.CounterMode = TIM_COUNTERMODE_UP;
  htim8.Init.Period = 65535;
  htim8.Init.ClockDivision = TIM_CLOCKDIVISION_DIV1;
  htim8.Init.RepetitionCounter = 0;
  htim8.Init.AutoReloadPreload = TIM_AUTORELOAD_PRELOAD_DISABLE;
  sConfig.EncoderMode = TIM_ENCODERMODE_TI12;
  sConfig.IC1Polarity = TIM_ICPOLARITY_RISING;
  sConfig.IC1Selection = TIM_ICSELECTION_DIRECTTI;
  sConfig.IC1Prescaler = TIM_ICPSC_DIV1;
  sConfig.IC1Filter = 0;
  sConfig.IC2Polarity = TIM_ICPOLARITY_RISING;
  sConfig.IC2Selection = TIM_ICSELECTION_DIRECTTI;
  sConfig.IC2Prescaler = TIM_ICPSC_DIV1;
  sConfig.IC2Filter = 0;
  if (HAL_TIM_Encoder_Init(&htim8, &sConfig) != HAL_OK)
  {
    Error_Handler();
  }
  sMasterConfig.MasterOutputTrigger = TIM_TRGO_RESET;
  sMasterConfig.MasterOutputTrigger2 = TIM_TRGO2_RESET;
  sMasterConfig.MasterSlaveMode = TIM_MASTERSLAVEMODE_DISABLE;
  if (HAL_TIMEx_MasterConfigSynchronization(&htim8, &sMasterConfig) != HAL_OK)
  {
    Error_Handler();
  }

}

static void MX_TIM12_Init(void)
{

  TIM_MasterConfigTypeDef sMasterConfig = {0};
  TIM_OC_InitTypeDef sConfigOC = {0};

  htim12.Instance = TIM12;
  htim12.Init.Prescaler = 59;
  htim12.Init.CounterMode = TIM_COUNTERMODE_UP;
  htim12.Init.Period = 64000;
  htim12.Init.ClockDivision = TIM_CLOCKDIVISION_DIV1;
  htim12.Init.AutoReloadPreload = TIM_AUTORELOAD_PRELOAD_DISABLE;
  if (HAL_TIM_PWM_Init(&htim12) != HAL_OK)
  {
    Error_Handler();
  }
  sMasterConfig.MasterOutputTrigger = TIM_TRGO_RESET;
  sMasterConfig.MasterSlaveMode = TIM_MASTERSLAVEMODE_DISABLE;
  if (HAL_TIMEx_MasterConfigSynchronization(&htim12, &sMasterConfig) != HAL_OK)
  {
    Error_Handler();
  }
  sConfigOC.OCMode = TIM_OCMODE_PWM1;
  sConfigOC.Pulse = 0;
  sConfigOC.OCPolarity = TIM_OCPOLARITY_HIGH;
  sConfigOC.OCFastMode = TIM_OCFAST_DISABLE;
  if (HAL_TIM_PWM_ConfigChannel(&htim12, &sConfigOC, TIM_CHANNEL_2) != HAL_OK)
  {
    Error_Handler();
  }
  HAL_TIM_MspPostInit(&htim12);

}

static void MX_TIM13_Init(void)
{

  TIM_OC_InitTypeDef sConfigOC = {0};

  htim13.Instance = TIM13;
  htim13.Init.Prescaler = 59;
  htim13.Init.CounterMode = TIM_COUNTERMODE_UP;
  htim13.Init.Period = 64000;
  htim13.Init.ClockDivision = TIM_CLOCKDIVISION_DIV1;
  htim13.Init.AutoReloadPreload = TIM_AUTORELOAD_PRELOAD_DISABLE;
  if (HAL_TIM_Base_Init(&htim13) != HAL_OK)
  {
    Error_Handler();
  }
  if (HAL_TIM_PWM_Init(&htim13) != HAL_OK)
  {
    Error_Handler();
  }
  sConfigOC.OCMode = TIM_OCMODE_PWM1;
  sConfigOC.Pulse = 0;
  sConfigOC.OCPolarity = TIM_OCPOLARITY_HIGH;
  sConfigOC.OCFastMode = TIM_OCFAST_DISABLE;
  if (HAL_TIM_PWM_ConfigChannel(&htim13, &sConfigOC, TIM_CHANNEL_1) != HAL_OK)
  {
    Error_Handler();
  }
  HAL_TIM_MspPostInit(&htim13);

}

static void MX_TIM14_Init(void)
{

  TIM_OC_InitTypeDef sConfigOC = {0};

  htim14.Instance = TIM14;
  htim14.Init.Prescaler = 59;
  htim14.Init.CounterMode = TIM_COUNTERMODE_UP;
  htim14.Init.Period = 64000;
  htim14.Init.ClockDivision = TIM_CLOCKDIVISION_DIV1;
  htim14.Init.AutoReloadPreload = TIM_AUTORELOAD_PRELOAD_DISABLE;
  if (HAL_TIM_Base_Init(&htim14) != HAL_OK)
  {
    Error_Handler();
  }
  if (HAL_TIM_PWM_Init(&htim14) != HAL_OK)
  {
    Error_Handler();
  }
  sConfigOC.OCMode = TIM_OCMODE_PWM1;
  sConfigOC.Pulse = 0;
  sConfigOC.OCPolarity = TIM_OCPOLARITY_HIGH;
  sConfigOC.OCFastMode = TIM_OCFAST_DISABLE;
  if (HAL_TIM_PWM_ConfigChannel(&htim14, &sConfigOC, TIM_CHANNEL_1) != HAL_OK)
  {
    Error_Handler();
  }
  HAL_TIM_MspPostInit(&htim14);

}

static void MX_TIM15_Init(void)
{

  TIM_MasterConfigTypeDef sMasterConfig = {0};
  TIM_OC_InitTypeDef sConfigOC = {0};
  TIM_BreakDeadTimeConfigTypeDef sBreakDeadTimeConfig = {0};

  htim15.Instance = TIM15;
  htim15.Init.Prescaler = 0;
  htim15.Init.CounterMode = TIM_COUNTERMODE_UP;
  htim15.Init.Period = 9600;
  htim15.Init.ClockDivision = TIM_CLOCKDIVISION_DIV1;
  htim15.Init.RepetitionCounter = 0;
  htim15.Init.AutoReloadPreload = TIM_AUTORELOAD_PRELOAD_DISABLE;
  if (HAL_TIM_PWM_Init(&htim15) != HAL_OK)
  {
    Error_Handler();
  }
  sMasterConfig.MasterOutputTrigger = TIM_TRGO_RESET;
  sMasterConfig.MasterSlaveMode = TIM_MASTERSLAVEMODE_DISABLE;
  if (HAL_TIMEx_MasterConfigSynchronization(&htim15, &sMasterConfig) != HAL_OK)
  {
    Error_Handler();
  }
  sConfigOC.OCMode = TIM_OCMODE_PWM1;
  sConfigOC.Pulse = 0;
  sConfigOC.OCPolarity = TIM_OCPOLARITY_HIGH;
  sConfigOC.OCNPolarity = TIM_OCNPOLARITY_HIGH;
  sConfigOC.OCFastMode = TIM_OCFAST_DISABLE;
  sConfigOC.OCIdleState = TIM_OCIDLESTATE_RESET;
  sConfigOC.OCNIdleState = TIM_OCNIDLESTATE_RESET;
  if (HAL_TIM_PWM_ConfigChannel(&htim15, &sConfigOC, TIM_CHANNEL_1) != HAL_OK)
  {
    Error_Handler();
  }
  if (HAL_TIM_PWM_ConfigChannel(&htim15, &sConfigOC, TIM_CHANNEL_2) != HAL_OK)
  {
    Error_Handler();
  }
  sBreakDeadTimeConfig.OffStateRunMode = TIM_OSSR_DISABLE;
  sBreakDeadTimeConfig.OffStateIDLEMode = TIM_OSSI_DISABLE;
  sBreakDeadTimeConfig.LockLevel = TIM_LOCKLEVEL_OFF;
  sBreakDeadTimeConfig.DeadTime = 0;
  sBreakDeadTimeConfig.BreakState = TIM_BREAK_DISABLE;
  sBreakDeadTimeConfig.BreakPolarity = TIM_BREAKPOLARITY_HIGH;
  sBreakDeadTimeConfig.BreakFilter = 0;
  sBreakDeadTimeConfig.AutomaticOutput = TIM_AUTOMATICOUTPUT_DISABLE;
  if (HAL_TIMEx_ConfigBreakDeadTime(&htim15, &sBreakDeadTimeConfig) != HAL_OK)
  {
    Error_Handler();
  }
  HAL_TIM_MspPostInit(&htim15);

}

static void MX_TIM16_Init(void)
{

  TIM_OC_InitTypeDef sConfigOC = {0};
  TIM_BreakDeadTimeConfigTypeDef sBreakDeadTimeConfig = {0};

  htim16.Instance = TIM16;
  htim16.Init.Prescaler = 0;
  htim16.Init.CounterMode = TIM_COUNTERMODE_UP;
  htim16.Init.Period = 9600;
  htim16.Init.ClockDivision = TIM_CLOCKDIVISION_DIV1;
  htim16.Init.RepetitionCounter = 0;
  htim16.Init.AutoReloadPreload = TIM_AUTORELOAD_PRELOAD_DISABLE;
  if (HAL_TIM_Base_Init(&htim16) != HAL_OK)
  {
    Error_Handler();
  }
  if (HAL_TIM_PWM_Init(&htim16) != HAL_OK)
  {
    Error_Handler();
  }
  sConfigOC.OCMode = TIM_OCMODE_PWM1;
  sConfigOC.Pulse = 10000;
  sConfigOC.OCPolarity = TIM_OCPOLARITY_HIGH;
  sConfigOC.OCNPolarity = TIM_OCNPOLARITY_HIGH;
  sConfigOC.OCFastMode = TIM_OCFAST_DISABLE;
  sConfigOC.OCIdleState = TIM_OCIDLESTATE_RESET;
  sConfigOC.OCNIdleState = TIM_OCNIDLESTATE_RESET;
  if (HAL_TIM_PWM_ConfigChannel(&htim16, &sConfigOC, TIM_CHANNEL_1) != HAL_OK)
  {
    Error_Handler();
  }
  sBreakDeadTimeConfig.OffStateRunMode = TIM_OSSR_DISABLE;
  sBreakDeadTimeConfig.OffStateIDLEMode = TIM_OSSI_DISABLE;
  sBreakDeadTimeConfig.LockLevel = TIM_LOCKLEVEL_OFF;
  sBreakDeadTimeConfig.DeadTime = 0;
  sBreakDeadTimeConfig.BreakState = TIM_BREAK_DISABLE;
  sBreakDeadTimeConfig.BreakPolarity = TIM_BREAKPOLARITY_HIGH;
  sBreakDeadTimeConfig.BreakFilter = 0;
  sBreakDeadTimeConfig.AutomaticOutput = TIM_AUTOMATICOUTPUT_DISABLE;
  if (HAL_TIMEx_ConfigBreakDeadTime(&htim16, &sBreakDeadTimeConfig) != HAL_OK)
  {
    Error_Handler();
  }
  HAL_TIM_MspPostInit(&htim16);

}

static void MX_TIM17_Init(void)
{

  TIM_OC_InitTypeDef sConfigOC = {0};
  TIM_BreakDeadTimeConfigTypeDef sBreakDeadTimeConfig = {0};

  htim17.Instance = TIM17;
  htim17.Init.Prescaler = 0;
  htim17.Init.CounterMode = TIM_COUNTERMODE_UP;
  htim17.Init.Period = 9600;
  htim17.Init.ClockDivision = TIM_CLOCKDIVISION_DIV1;
  htim17.Init.RepetitionCounter = 0;
  htim17.Init.AutoReloadPreload = TIM_AUTORELOAD_PRELOAD_DISABLE;
  if (HAL_TIM_Base_Init(&htim17) != HAL_OK)
  {
    Error_Handler();
  }
  if (HAL_TIM_PWM_Init(&htim17) != HAL_OK)
  {
    Error_Handler();
  }
  sConfigOC.OCMode = TIM_OCMODE_PWM1;
  sConfigOC.Pulse = 45000;
  sConfigOC.OCPolarity = TIM_OCPOLARITY_HIGH;
  sConfigOC.OCNPolarity = TIM_OCNPOLARITY_HIGH;
  sConfigOC.OCFastMode = TIM_OCFAST_DISABLE;
  sConfigOC.OCIdleState = TIM_OCIDLESTATE_RESET;
  sConfigOC.OCNIdleState = TIM_OCNIDLESTATE_RESET;
  if (HAL_TIM_PWM_ConfigChannel(&htim17, &sConfigOC, TIM_CHANNEL_1) != HAL_OK)
  {
    Error_Handler();
  }
  sBreakDeadTimeConfig.OffStateRunMode = TIM_OSSR_DISABLE;
  sBreakDeadTimeConfig.OffStateIDLEMode = TIM_OSSI_DISABLE;
  sBreakDeadTimeConfig.LockLevel = TIM_LOCKLEVEL_OFF;
  sBreakDeadTimeConfig.DeadTime = 0;
  sBreakDeadTimeConfig.BreakState = TIM_BREAK_DISABLE;
  sBreakDeadTimeConfig.BreakPolarity = TIM_BREAKPOLARITY_HIGH;
  sBreakDeadTimeConfig.BreakFilter = 0;
  sBreakDeadTimeConfig.AutomaticOutput = TIM_AUTOMATICOUTPUT_DISABLE;
  if (HAL_TIMEx_ConfigBreakDeadTime(&htim17, &sBreakDeadTimeConfig) != HAL_OK)
  {
    Error_Handler();
  }
  HAL_TIM_MspPostInit(&htim17);

}

static void MX_UART5_Init(void)
{

  huart5.Instance = UART5;
  huart5.Init.BaudRate = 8000000;
  huart5.Init.WordLength = UART_WORDLENGTH_8B;
  huart5.Init.StopBits = UART_STOPBITS_1;
  huart5.Init.Parity = UART_PARITY_NONE;
  huart5.Init.Mode = UART_MODE_TX;
  huart5.Init.HwFlowCtl = UART_HWCONTROL_NONE;
  huart5.Init.OverSampling = UART_OVERSAMPLING_8;
  huart5.Init.OneBitSampling = UART_ONE_BIT_SAMPLE_DISABLE;
  huart5.Init.ClockPrescaler = UART_PRESCALER_DIV1;
  huart5.AdvancedInit.AdvFeatureInit = UART_ADVFEATURE_TXINVERT_INIT;
  huart5.AdvancedInit.TxPinLevelInvert = UART_ADVFEATURE_TXINV_ENABLE;
  if (HAL_UART_Init(&huart5) != HAL_OK)
  {
    Error_Handler();
  }
  if (HAL_UARTEx_SetTxFifoThreshold(&huart5, UART_TXFIFO_THRESHOLD_1_8) != HAL_OK)
  {
    Error_Handler();
  }
  if (HAL_UARTEx_SetRxFifoThreshold(&huart5, UART_RXFIFO_THRESHOLD_1_8) != HAL_OK)
  {
    Error_Handler();
  }
  if (HAL_UARTEx_DisableFifoMode(&huart5) != HAL_OK)
  {
    Error_Handler();
  }

}

static void MX_USART2_UART_Init(void)
{

  huart2.Instance = USART2;
  huart2.Init.BaudRate = 1000000;
  huart2.Init.WordLength = UART_WORDLENGTH_8B;
  huart2.Init.StopBits = UART_STOPBITS_1;
  huart2.Init.Parity = UART_PARITY_NONE;
  huart2.Init.Mode = UART_MODE_TX_RX;
  huart2.Init.HwFlowCtl = UART_HWCONTROL_NONE;
  huart2.Init.OverSampling = UART_OVERSAMPLING_16;
  huart2.Init.OneBitSampling = UART_ONE_BIT_SAMPLE_DISABLE;
  huart2.Init.ClockPrescaler = UART_PRESCALER_DIV1;
  huart2.AdvancedInit.AdvFeatureInit = UART_ADVFEATURE_NO_INIT;
  if (HAL_RS485Ex_Init(&huart2, UART_DE_POLARITY_HIGH, 25, 25) != HAL_OK)
  {
    Error_Handler();
  }
  if (HAL_UARTEx_SetTxFifoThreshold(&huart2, UART_TXFIFO_THRESHOLD_1_8) != HAL_OK)
  {
    Error_Handler();
  }
  if (HAL_UARTEx_SetRxFifoThreshold(&huart2, UART_RXFIFO_THRESHOLD_1_8) != HAL_OK)
  {
    Error_Handler();
  }
  if (HAL_UARTEx_DisableFifoMode(&huart2) != HAL_OK)
  {
    Error_Handler();
  }

}

static void MX_USART3_UART_Init(void)
{

  huart3.Instance = USART3;
  huart3.Init.BaudRate = 115200;
  huart3.Init.WordLength = UART_WORDLENGTH_8B;
  huart3.Init.StopBits = UART_STOPBITS_1;
  huart3.Init.Parity = UART_PARITY_NONE;
  huart3.Init.Mode = UART_MODE_TX_RX;
  huart3.Init.HwFlowCtl = UART_HWCONTROL_NONE;
  huart3.Init.OverSampling = UART_OVERSAMPLING_16;
  huart3.Init.OneBitSampling = UART_ONE_BIT_SAMPLE_DISABLE;
  huart3.Init.ClockPrescaler = UART_PRESCALER_DIV1;
  huart3.AdvancedInit.AdvFeatureInit = UART_ADVFEATURE_NO_INIT;
  if (HAL_UART_Init(&huart3) != HAL_OK)
  {
    Error_Handler();
  }
  if (HAL_UARTEx_SetTxFifoThreshold(&huart3, UART_TXFIFO_THRESHOLD_1_8) != HAL_OK)
  {
    Error_Handler();
  }
  if (HAL_UARTEx_SetRxFifoThreshold(&huart3, UART_RXFIFO_THRESHOLD_1_8) != HAL_OK)
  {
    Error_Handler();
  }
  if (HAL_UARTEx_DisableFifoMode(&huart3) != HAL_OK)
  {
    Error_Handler();
  }

}

static void MX_USART6_UART_Init(void)
{

  huart6.Instance = USART6;
  huart6.Init.BaudRate = 230400;
  huart6.Init.WordLength = UART_WORDLENGTH_8B;
  huart6.Init.StopBits = UART_STOPBITS_1;
  huart6.Init.Parity = UART_PARITY_NONE;
  huart6.Init.Mode = UART_MODE_TX_RX;
  huart6.Init.HwFlowCtl = UART_HWCONTROL_NONE;
  huart6.Init.OverSampling = UART_OVERSAMPLING_16;
  huart6.Init.OneBitSampling = UART_ONE_BIT_SAMPLE_DISABLE;
  huart6.Init.ClockPrescaler = UART_PRESCALER_DIV1;
  huart6.AdvancedInit.AdvFeatureInit = UART_ADVFEATURE_NO_INIT;
  if (HAL_UART_Init(&huart6) != HAL_OK)
  {
    Error_Handler();
  }
  if (HAL_UARTEx_SetTxFifoThreshold(&huart6, UART_TXFIFO_THRESHOLD_1_8) != HAL_OK)
  {
    Error_Handler();
  }
  if (HAL_UARTEx_SetRxFifoThreshold(&huart6, UART_RXFIFO_THRESHOLD_1_8) != HAL_OK)
  {
    Error_Handler();
  }
  if (HAL_UARTEx_DisableFifoMode(&huart6) != HAL_OK)
  {
    Error_Handler();
  }

}

static void MX_DMA_Init(void)
{

  /* DMA controller clock enable */
  __HAL_RCC_DMA1_CLK_ENABLE();

  /* DMA interrupt init */
  /* DMA1_Stream0_IRQn interrupt configuration */
  HAL_NVIC_SetPriority(DMA1_Stream0_IRQn, 0, 0);
  HAL_NVIC_EnableIRQ(DMA1_Stream0_IRQn);
  /* DMA1_Stream1_IRQn interrupt configuration */
  HAL_NVIC_SetPriority(DMA1_Stream1_IRQn, 0, 0);
  HAL_NVIC_EnableIRQ(DMA1_Stream1_IRQn);
  /* DMA1_Stream2_IRQn interrupt configuration */
  HAL_NVIC_SetPriority(DMA1_Stream2_IRQn, 5, 0);
  HAL_NVIC_EnableIRQ(DMA1_Stream2_IRQn);

}

static void MX_GPIO_Init(void)
{
  GPIO_InitTypeDef GPIO_InitStruct = {0};

  /* GPIO Ports Clock Enable */
  __HAL_RCC_GPIOE_CLK_ENABLE();
  __HAL_RCC_GPIOC_CLK_ENABLE();
  __HAL_RCC_GPIOF_CLK_ENABLE();
  __HAL_RCC_GPIOH_CLK_ENABLE();
  __HAL_RCC_GPIOA_CLK_ENABLE();
  __HAL_RCC_GPIOB_CLK_ENABLE();
  __HAL_RCC_GPIOD_CLK_ENABLE();
  __HAL_RCC_GPIOG_CLK_ENABLE();

  /*Configure GPIO pin Output Level */
  HAL_GPIO_WritePin(GPIOE, Mot1_Sens1_Pin|Mot2_Sens1_Pin|Mot1_Sens2_Pin|LED4_Pin
                          |LED5_Pin|LED6_Pin|Mot3_Sens2_Pin|Mot3_Sens1_Pin
                          |LED7_Pin|LED2_Pin, GPIO_PIN_RESET);

  /*Configure GPIO pin Output Level */
  HAL_GPIO_WritePin(SPI_MOSI_GPIO_Port, SPI_MOSI_Pin, GPIO_PIN_RESET);

  /*Configure GPIO pin Output Level */
  HAL_GPIO_WritePin(GPIOF, Mot4_Sens1_Pin|Mot4_Sens2_Pin, GPIO_PIN_RESET);

  /*Configure GPIO pin Output Level */
  HAL_GPIO_WritePin(LED3_GPIO_Port, LED3_Pin, GPIO_PIN_SET);

  /*Configure GPIO pin Output Level */
  HAL_GPIO_WritePin(GPIOD, USB_OTG_FS_PWR_EN_Pin|Mot2_Sens2_Pin, GPIO_PIN_RESET);

  /*Configure GPIO pin Output Level */
  HAL_GPIO_WritePin(GPIOC, SPI_CS1_Pin|SPI_CS2_Pin|SPI_SCK_Pin|SPI_MISO_Pin, GPIO_PIN_RESET);

  /*Configure GPIO pins : Mot1_Sens1_Pin Mot2_Sens1_Pin Mot1_Sens2_Pin LED4_Pin
                           LED5_Pin LED6_Pin Mot3_Sens2_Pin Mot3_Sens1_Pin
                           LED7_Pin LED2_Pin */
  GPIO_InitStruct.Pin = Mot1_Sens1_Pin|Mot2_Sens1_Pin|Mot1_Sens2_Pin|LED4_Pin
                          |LED5_Pin|LED6_Pin|Mot3_Sens2_Pin|Mot3_Sens1_Pin
                          |LED7_Pin|LED2_Pin;
  GPIO_InitStruct.Mode = GPIO_MODE_OUTPUT_PP;
  GPIO_InitStruct.Pull = GPIO_NOPULL;
  GPIO_InitStruct.Speed = GPIO_SPEED_FREQ_LOW;
  HAL_GPIO_Init(GPIOE, &GPIO_InitStruct);

  /*Configure GPIO pins : Etor1_Pin Etor2_Pin */
  GPIO_InitStruct.Pin = Etor1_Pin|Etor2_Pin;
  GPIO_InitStruct.Mode = GPIO_MODE_INPUT;
  GPIO_InitStruct.Pull = GPIO_PULLUP;
  HAL_GPIO_Init(GPIOC, &GPIO_InitStruct);

  /*Configure GPIO pins : SPI_MOSI_Pin LED3_Pin */
  GPIO_InitStruct.Pin = SPI_MOSI_Pin|LED3_Pin;
  GPIO_InitStruct.Mode = GPIO_MODE_OUTPUT_PP;
  GPIO_InitStruct.Pull = GPIO_NOPULL;
  GPIO_InitStruct.Speed = GPIO_SPEED_FREQ_LOW;
  HAL_GPIO_Init(GPIOB, &GPIO_InitStruct);

  /*Configure GPIO pins : Mot4_Sens1_Pin Mot4_Sens2_Pin */
  GPIO_InitStruct.Pin = Mot4_Sens1_Pin|Mot4_Sens2_Pin;
  GPIO_InitStruct.Mode = GPIO_MODE_OUTPUT_PP;
  GPIO_InitStruct.Pull = GPIO_NOPULL;
  GPIO_InitStruct.Speed = GPIO_SPEED_FREQ_LOW;
  HAL_GPIO_Init(GPIOF, &GPIO_InitStruct);

  /*Configure GPIO pins : USB_OTG_FS_PWR_EN_Pin Mot2_Sens2_Pin */
  GPIO_InitStruct.Pin = USB_OTG_FS_PWR_EN_Pin|Mot2_Sens2_Pin;
  GPIO_InitStruct.Mode = GPIO_MODE_OUTPUT_PP;
  GPIO_InitStruct.Pull = GPIO_NOPULL;
  GPIO_InitStruct.Speed = GPIO_SPEED_FREQ_LOW;
  HAL_GPIO_Init(GPIOD, &GPIO_InitStruct);

  /*Configure GPIO pins : SPI_CS1_Pin SPI_CS2_Pin SPI_SCK_Pin SPI_MISO_Pin */
  GPIO_InitStruct.Pin = SPI_CS1_Pin|SPI_CS2_Pin|SPI_SCK_Pin|SPI_MISO_Pin;
  GPIO_InitStruct.Mode = GPIO_MODE_OUTPUT_PP;
  GPIO_InitStruct.Pull = GPIO_NOPULL;
  GPIO_InitStruct.Speed = GPIO_SPEED_FREQ_LOW;
  HAL_GPIO_Init(GPIOC, &GPIO_InitStruct);

  /*Configure GPIO pins : PA8 PA11 PA12 */
  GPIO_InitStruct.Pin = GPIO_PIN_8|GPIO_PIN_11|GPIO_PIN_12;
  GPIO_InitStruct.Mode = GPIO_MODE_AF_PP;
  GPIO_InitStruct.Pull = GPIO_NOPULL;
  GPIO_InitStruct.Speed = GPIO_SPEED_FREQ_LOW;
  GPIO_InitStruct.Alternate = GPIO_AF10_OTG1_FS;
  HAL_GPIO_Init(GPIOA, &GPIO_InitStruct);

  /*Configure GPIO pins : Etor3_Pin Etor4_Pin */
  GPIO_InitStruct.Pin = Etor3_Pin|Etor4_Pin;
  GPIO_InitStruct.Mode = GPIO_MODE_INPUT;
  GPIO_InitStruct.Pull = GPIO_PULLUP;
  HAL_GPIO_Init(GPIOB, &GPIO_InitStruct);

}

void Error_Handler(void)
{
  __disable_irq();
  while (1)
  {
  }
}
